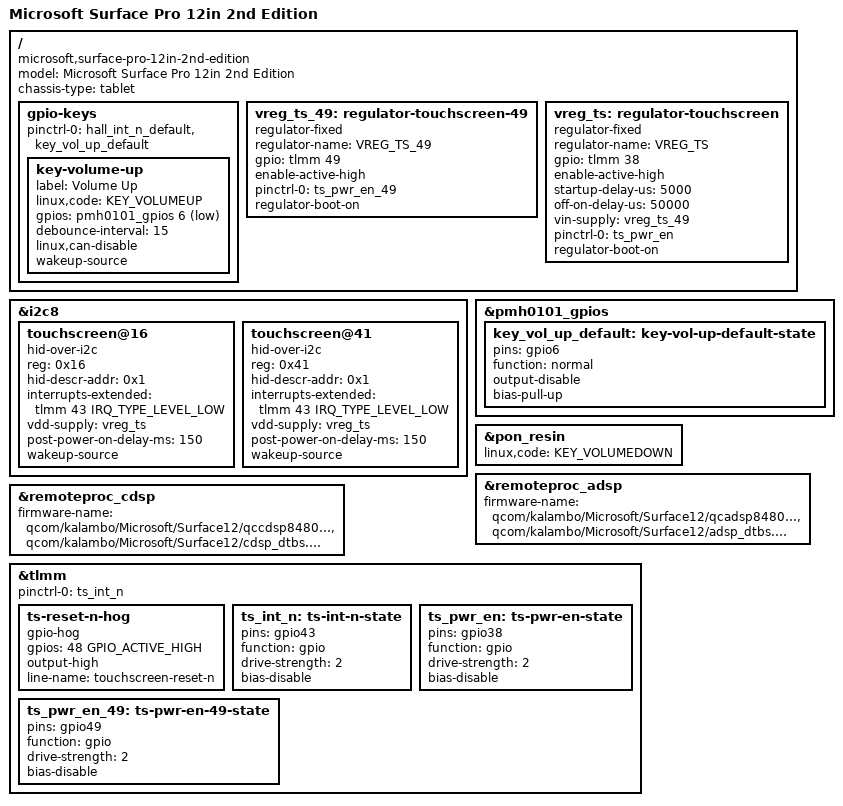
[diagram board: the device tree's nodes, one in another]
// SPDX-License-Identifier: BSD-3-Clause
/*
 * Microsoft Surface Pro 12-inch (2nd Edition), models 2148 and 2149, with
 * the 6-core Snapdragon X2 Plus X2P-42-100 (Kalambo).
 *
 * Written from the ACPI tables in Microsoft's firmware download
 * (Surface_UEFI_8.5175.155). Next to the parts kalambo-microsoft-surface.dtsi
 * shares with the Surface Laptop 13-inch (2nd Edition), the tablet has a
 * touchscreen whose address depends on the board ID (MSHW0824 at 0x16 or
 * MSHW0826 at 0x41) and volume buttons. It has neither the multiport nor
 * the USB 2.0 controller (ACPI USB3 and USB4 _STA 0); the type cover is
 * reached through the Surface Serial Hub.
 *
 * Its storage is UFS (INA4230 channels STORAGE_UFS_1P2V and
 * STORAGE_UFS_2P5V), which glymur.dtsi does not describe yet.
 *
 * Copyright (c) Qualcomm Technologies, Inc. and/or its subsidiaries.
 */
/dts-v1/;

#include "kalambo.dtsi"
#include "kalambo-microsoft-surface.dtsi"

/ {
	model = "Microsoft Surface Pro 12in 2nd Edition";
	compatible = "microsoft,surface-pro-12in-2nd-edition", "qcom,kalambo";
	chassis-type = "tablet";

	/*
	 * ACPI MSBT (MSHW0040) lists PM01 pins 0x72 and 0x208 for the volume
	 * buttons. The ACPI tables of the reference design list the same two
	 * pins, and glymur-crd.dtsi has volume up on PMH0101 GPIO 6 and volume
	 * down on RESIN.
	 */
	gpio-keys {
		pinctrl-0 = <&hall_int_n_default>, <&key_vol_up_default>;

		key-volume-up {
			label = "Volume Up";
			linux,code = <KEY_VOLUMEUP>;
			gpios = <&pmh0101_gpios 6 GPIO_ACTIVE_LOW>;
			debounce-interval = <15>;
			linux,can-disable;
			wakeup-source;
		};
	};

	/*
	 * The touchscreen's power table (\_SB.PEP0.LIXC, device \_SB.ITCH):
	 * D0 drives TLMM 49 and then TLMM 38 high, waits 5 ms, drives TLMM 48
	 * high and waits 150 ms. D3 drives 49 and 38 low, waits 50 ms and
	 * drives 48 low.
	 */
	vreg_ts_49: regulator-touchscreen-49 {
		compatible = "regulator-fixed";

		regulator-name = "VREG_TS_49";

		gpio = <&tlmm 49 GPIO_ACTIVE_HIGH>;
		enable-active-high;

		pinctrl-0 = <&ts_pwr_en_49>;
		pinctrl-names = "default";

		regulator-boot-on;
	};

	vreg_ts: regulator-touchscreen {
		compatible = "regulator-fixed";

		regulator-name = "VREG_TS";

		gpio = <&tlmm 38 GPIO_ACTIVE_HIGH>;
		enable-active-high;
		startup-delay-us = <5000>;
		off-on-delay-us = <50000>;

		vin-supply = <&vreg_ts_49>;

		pinctrl-0 = <&ts_pwr_en>;
		pinctrl-names = "default";

		regulator-boot-on;
	};
};

/*
 * ACPI \_SB.ITCH on I2C9 at 400 kHz, HID descriptor register 1 (its _DSM
 * function 1 returns 1), interrupt GIO0 virtual pin 0x400 level low: the
 * thirteenth interrupt after the four summary interrupts of GIO0._CRS,
 * GSIV 0x103d, is SPI 4125, PDC pin 192, TLMM 43. _INI sets the address
 * from the board ID (TBID): 0x16 (MSHW0824) for 0x0c and 0x0e, 0x41
 * (MSHW0826) for 0x09, 0x0a and 0x0d. Both are described; i2c-hid gives up
 * on the absent one before it asks for the interrupt. Neither node owns
 * the reset line, TLMM 48, which the hog below holds high.
 */
&i2c8 {
	touchscreen@16 {
		compatible = "hid-over-i2c";
		reg = <0x16>;
		hid-descr-addr = <0x1>;
		interrupts-extended = <&tlmm 43 IRQ_TYPE_LEVEL_LOW>;

		vdd-supply = <&vreg_ts>;
		post-power-on-delay-ms = <150>;

		wakeup-source;
	};

	touchscreen@41 {
		compatible = "hid-over-i2c";
		reg = <0x41>;
		hid-descr-addr = <0x1>;
		interrupts-extended = <&tlmm 43 IRQ_TYPE_LEVEL_LOW>;

		vdd-supply = <&vreg_ts>;
		post-power-on-delay-ms = <150>;

		wakeup-source;
	};
};

&pmh0101_gpios {
	key_vol_up_default: key-vol-up-default-state {
		pins = "gpio6";
		function = "normal";
		output-disable;
		bias-pull-up;
	};
};

&pon_resin {
	linux,code = <KEY_VOLUMEDOWN>;

	status = "okay";
};

&remoteproc_adsp {
	firmware-name = "qcom/kalambo/Microsoft/Surface12/qcadsp8480.mbn",
			"qcom/kalambo/Microsoft/Surface12/adsp_dtbs.elf";

	status = "okay";
};

&remoteproc_cdsp {
	firmware-name = "qcom/kalambo/Microsoft/Surface12/qccdsp8480.mbn",
			"qcom/kalambo/Microsoft/Surface12/cdsp_dtbs.elf";

	status = "okay";
};

&tlmm {
	pinctrl-0 = <&ts_int_n>;
	pinctrl-names = "default";

	ts-reset-n-hog {
		gpio-hog;
		gpios = <48 GPIO_ACTIVE_HIGH>;
		output-high;
		line-name = "touchscreen-reset-n";
	};

	ts_int_n: ts-int-n-state {
		pins = "gpio43";
		function = "gpio";
		drive-strength = <2>;
		bias-disable;
	};

	ts_pwr_en: ts-pwr-en-state {
		pins = "gpio38";
		function = "gpio";
		drive-strength = <2>;
		bias-disable;
	};

	ts_pwr_en_49: ts-pwr-en-49-state {
		pins = "gpio49";
		function = "gpio";
		drive-strength = <2>;
		bias-disable;
	};
};
